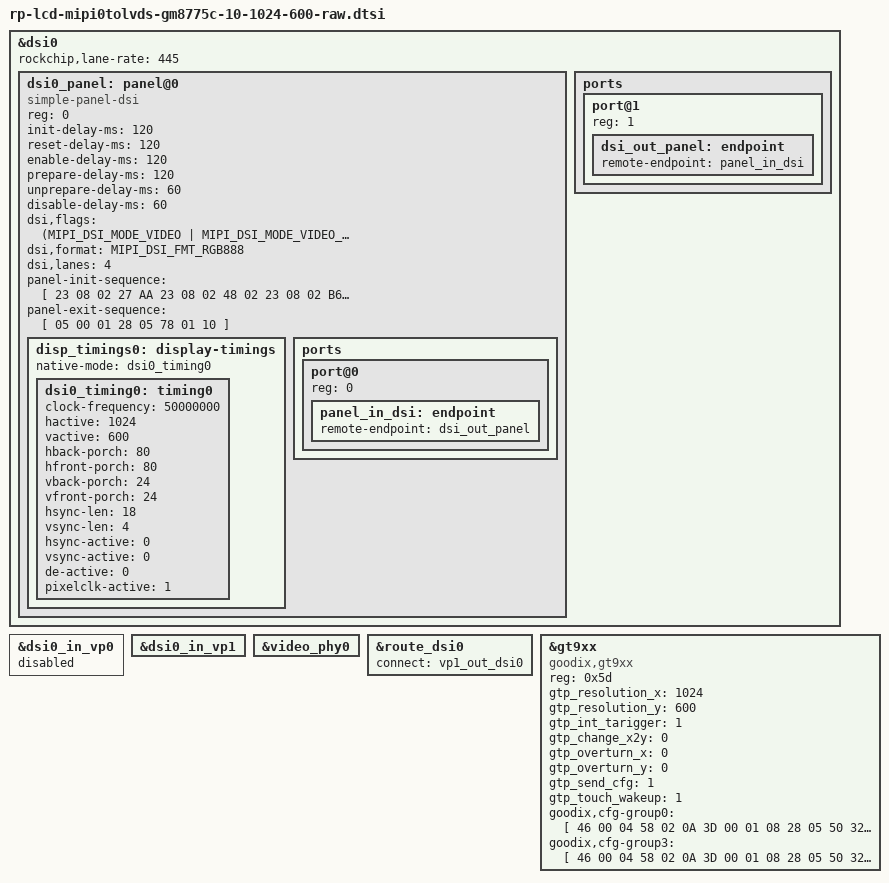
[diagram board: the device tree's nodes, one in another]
#include "rp-lcd-hdmi.dtsi"
#define RP_SINGLE_LCD
#define RP_MIPI02LVDS


&dsi0 {
    status = "okay";
    rockchip,lane-rate = <445>;

    dsi0_panel: panel@0 {
        status = "okay";
        compatible = "simple-panel-dsi";
        reg = <0>;

        init-delay-ms = <120>;
        reset-delay-ms = <120>;
        enable-delay-ms = <120>;
        prepare-delay-ms = <120>;
        unprepare-delay-ms = <60>;
        disable-delay-ms = <60>;
        dsi,flags = <(MIPI_DSI_MODE_VIDEO | MIPI_DSI_MODE_VIDEO_BURST |
                        MIPI_DSI_MODE_LPM | MIPI_DSI_MODE_EOT_PACKET)>;
        dsi,format = <MIPI_DSI_FMT_RGB888>;
        dsi,lanes  = <4>;

        /**
         * power-supply = <>;
         * reset-gpios = <>;
         *
         * lcd reset pin and power supply
         * please refer to ***-lcd-gpio.dtsi
         * that included in main dts.
         */

        panel-init-sequence = [
            23 08 02 27 AA
            23 08 02 48 02
            23 08 02 B6 20
            23 08 02 01 00
            23 08 02 02 58
            23 08 02 03 24
            23 08 02 04 50
            23 08 02 05 12
            23 08 02 06 50
            23 08 02 07 00
            23 08 02 08 18
            23 08 02 09 04
            23 08 02 0A 18
            23 08 02 0B 82
            23 08 02 0C 1F
            23 08 02 0D 01
            23 08 02 0E 80
            23 08 02 0F 20
            23 08 02 10 20
            23 08 02 11 03
            23 08 02 12 1B
            23 08 02 13 07
            23 08 02 14 34
            23 08 02 15 20
            23 08 02 16 10
            23 08 02 17 00
            23 08 02 18 01
            23 08 02 19 23
            23 08 02 1A 40
            23 08 02 1B 00
            23 08 02 1E 46
            23 08 02 51 30
            23 08 02 1F 10
            23 08 02 2A 01
            
            05 78 01 11
            05 05 01 29
        ];

        panel-exit-sequence = [
            05 00 01 28
            05 78 01 10
        ];

        disp_timings0: display-timings {
            native-mode = <&dsi0_timing0>;
            
            dsi0_timing0: timing0 {
                clock-frequency = <50000000>;
                hactive = <1024>;
                vactive = <600>;
                hback-porch = <80>;
                hfront-porch = <80>;
                vback-porch = <24>;
                vfront-porch = <24>;
                hsync-len = <18>;
                vsync-len = <4>;
                hsync-active = <0>;
                vsync-active = <0>;
                de-active = <0>;
                pixelclk-active = <1>;
            };
        };

        ports {
            #address-cells = <1>;
            #size-cells = <0>;

            port@0 {
                reg = <0>;
				panel_in_dsi: endpoint {
					remote-endpoint = <&dsi_out_panel>;
                };
            };
        };
    };

    ports {
        #address-cells = <1>;
        #size-cells = <0>;

        port@1 {
            reg = <1>;
			dsi_out_panel: endpoint {
				remote-endpoint = <&panel_in_dsi>;
            };
        };
    };
};



&dsi0_in_vp0 {
	status = "disabled";
};

&dsi0_in_vp1 {
	status = "okay";
};


&video_phy0 {
	status = "okay";
};


&route_dsi0 {
	status = "okay";
	connect = <&vp1_out_dsi0>;
};



&gt9xx {
	status = "okay";
	compatible = "goodix,gt9xx";
	reg = <0x5d>;

	gtp_resolution_x = <1024>;
	gtp_resolution_y = <600>;
	gtp_int_tarigger = <1>;
	gtp_change_x2y = <0>;
	gtp_overturn_x = <0>;
	gtp_overturn_y = <0>;
	gtp_send_cfg = <1>;
	gtp_touch_wakeup = <1>;

	/**
	 * goodix_rst_gpio = <>;
	 * goodix_irq_gpio = <>;
	 *
	 * touch panel interrupt and reset pin
	 * please refer to ***-lcd-gpio.dtsi
	 * that included in main dts.
	 */
	
	goodix,cfg-group0 = [
	    46 00 04 58 02 0A 3D 00 01 08
	    28 05 50 32 03 05 00 00 00 00
	    00 00 00 18 1A 1E 14 8D 2D 88
	    17 15 31 0D 00 00 01 9B 03 1D
	    00 00 00 00 00 00 00 00 00 00
	    00 1E 5A 94 C5 02 08 00 00 00
	    61 21 00 57 29 00 4E 34 00 48
	    41 00 43 51 00 43 00 00 00 00
	    00 00 00 00 00 00 00 00 00 00
	    00 00 00 00 00 00 00 00 00 00
	    00 00 00 00 00 00 00 00 00 00
	    00 00 00 01 04 05 06 07 08 09
	    0C 0D 0E 0F 10 11 14 15 FF FF
	    FF FF 00 00 00 00 00 00 00 00
	    00 00 00 02 04 06 07 08 0A 0C
	    0F 10 11 12 13 19 1B 1C 1E 1F
	    20 21 22 23 24 25 26 27 FF FF
	    FF FF FF FF 00 00 00 00 00 00
	    00 00 00 00 FD 01];
	goodix,cfg-group3 = [
	    46 00 04 58 02 0A 3D 00 01 08
	    28 05 50 32 03 05 00 00 00 00
	    00 00 00 18 1A 1E 14 8D 2D 88
	    17 15 31 0D 00 00 01 9B 03 1D
	    00 00 00 00 00 00 00 00 00 00
	    00 1E 5A 94 C5 02 08 00 00 00
	    61 21 00 57 29 00 4E 34 00 48
	    41 00 43 51 00 43 00 00 00 00
	    00 00 00 00 00 00 00 00 00 00
	    00 00 00 00 00 00 00 00 00 00
	    00 00 00 00 00 00 00 00 00 00
	    00 00 00 01 04 05 06 07 08 09
	    0C 0D 0E 0F 10 11 14 15 FF FF
	    FF FF 00 00 00 00 00 00 00 00
	    00 00 00 02 04 06 07 08 0A 0C
	    0F 10 11 12 13 19 1B 1C 1E 1F
	    20 21 22 23 24 25 26 27 FF FF
	    FF FF FF FF 00 00 00 00 00 00
	    00 00 00 00 FD 01
	];
};
